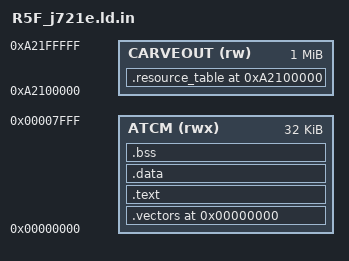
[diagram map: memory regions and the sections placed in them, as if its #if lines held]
#if R5F_CORE == 0
#define CARVEOUT_ORIGIN 0xa2100000
#else
#define CARVEOUT_ORIGIN 0xa4100000
#endif
ENTRY(_vectors)
MEMORY {
  ATCM     (rwx) : ORIGIN = 0x00000000, LENGTH = 0x00008000
  CARVEOUT (rw)  : ORIGIN = CARVEOUT_ORIGIN, LENGTH = 0x00100000
}
_stack_top = ORIGIN(ATCM) + LENGTH(ATCM);
_dbg_base  = CARVEOUT_ORIGIN + 0x400;
SECTIONS {
  .vectors 0x00000000 : { KEEP(*(.vectors)) } > ATCM
  .text : { *(.text.start) *(.text*) *(.rodata*) *(.glue_7*) } > ATCM
  .data : { *(.data*) } > ATCM
  .bss (NOLOAD) : { . = ALIGN(4); __bss_start = .; *(.bss*) *(COMMON); . = ALIGN(4); __bss_end = .; } > ATCM
  .resource_table CARVEOUT_ORIGIN : { KEEP(*(.resource_table)) } > CARVEOUT
  /DISCARD/ : { *(.ARM.exidx*) *(.ARM.extab*) *(.comment) *(.note*) *(.init*) *(.fini*) }
}
